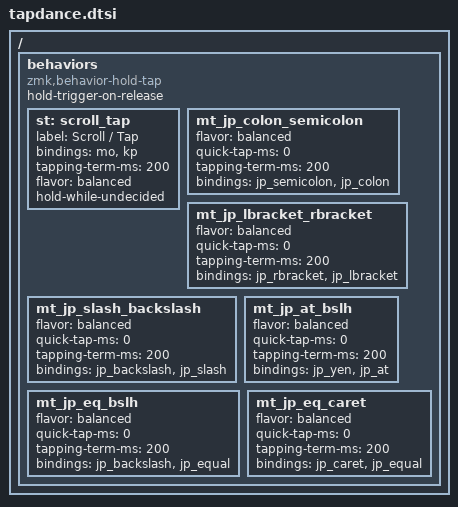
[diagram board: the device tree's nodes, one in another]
/ {
    behaviors {
        compatible = "zmk,behavior-hold-tap";
        hold-trigger-on-release; 
        
        st: scroll_tap {
            label = "Scroll / Tap";
            bindings = <&mo>, <&kp>;

            #binding-cells = <2>;
            tapping-term-ms = <200>;
            flavor = "balanced";
            hold-while-undecided;
        };
        mt_jp_colon_semicolon: mt_jp_colon_semicolon {
            #binding-cells = <2>;
            flavor = "balanced";
            quick-tap-ms = <0>;
            tapping-term-ms = <200>;
            bindings = <&jp_semicolon &jp_colon>;
        };

        mt_jp_lbracket_rbracket: mt_jp_lbracket_rbracket {
            #binding-cells = <2>;
            flavor = "balanced";
            quick-tap-ms = <0>;
            tapping-term-ms = <200>;
            bindings = <&jp_rbracket &jp_lbracket>;
        };

        mt_jp_slash_backslash: mt_jp_slash_backslash {
            #binding-cells = <2>;
            flavor = "balanced";
            quick-tap-ms = <0>;
            tapping-term-ms = <200>;
            bindings = <&jp_backslash &jp_slash>;
        };

        mt_jp_at_bslh: mt_jp_at_bslh {
            #binding-cells = <2>;
            flavor = "balanced";
            quick-tap-ms = <0>;
            tapping-term-ms = <200>;
            bindings = <&jp_yen &jp_at>;
        };

        mt_jp_eq_bslh: mt_jp_eq_bslh {
            #binding-cells = <2>;
            flavor = "balanced";
            quick-tap-ms = <0>;
            tapping-term-ms = <200>;
            bindings = <&jp_backslash &jp_equal>;
        };

        mt_jp_eq_caret: mt_jp_eq_caret {
            #binding-cells = <2>;
            flavor = "balanced";
            quick-tap-ms = <0>;
            tapping-term-ms = <200>;
            bindings = <&jp_caret &jp_equal>;
        };
    };
};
